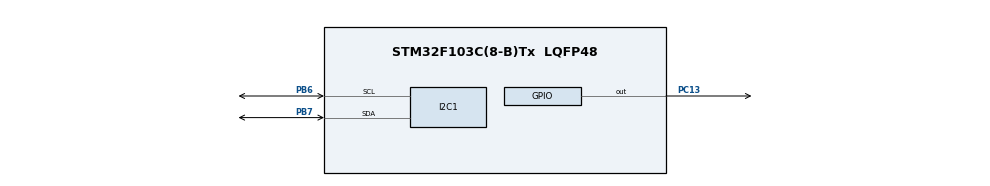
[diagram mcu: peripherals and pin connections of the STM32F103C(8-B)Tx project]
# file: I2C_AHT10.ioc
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I2C1.I2C_Mode=I2C_Fast
Mcu.Family=STM32F1
Mcu.Name=STM32F103C(8-B)Tx
Mcu.Package=LQFP48
NVIC.I2C1_EV_IRQn=true\:0\:0\:false\:false\:true\:true\:true
NVIC.PriorityGroup=NVIC_PRIORITYGROUP_4
NVIC.TIM4_IRQn=true\:0\:0\:false\:false\:true\:true\:true
PA13.Mode=Serial_Wire
PA13.Signal=SYS_JTMS-SWDIO
PA14.Mode=Serial_Wire
PA14.Signal=SYS_JTCK-SWCLK
PB6.Mode=I2C
PB6.Signal=I2C1_SCL
PB7.Mode=I2C
PB7.Signal=I2C1_SDA
PC13-TAMPER-RTC.PinState=GPIO_PIN_SET
PC13-TAMPER-RTC.Signal=GPIO_Output
ProjectManager.HeapSize=0x200
ProjectManager.StackSize=0x400
ProjectManager.TargetToolchain=MDK-ARM V5.27
RCC.APB1Freq_Value=8000000
RCC.APB2Freq_Value=8000000
TIM4.Period=1000-1
TIM4.Prescaler=800-1
VP_TIM4_VS_ClockSourceINT.Mode=Internal
board=custom

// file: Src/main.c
/* USER CODE BEGIN Header */
/**
  ******************************************************************************
  * @file           : main.c
  * @brief          : Main program body
  ******************************************************************************
  * @attention
  *
  * <h2><center>&copy; Copyright (c) 2020 STMicroelectronics.
  * All rights reserved.</center></h2>
  *
  * This software component is licensed by ST under BSD 3-Clause license,
  * the "License"; You may not use this file except in compliance with the
  * License. You may obtain a copy of the License at:
  *                        opensource.org/licenses/BSD-3-Clause
  *
  ******************************************************************************
  */
/* USER CODE END Header */

#include "main.h"

I2C_HandleTypeDef hi2c1;

TIM_HandleTypeDef htim4;

/* USER CODE BEGIN PV */

/* Variables for AHT10 */
uint8_t AHT10_RX_Data[6];
uint32_t AHT10_ADC_Raw;
float AHT10_Temperature;
float AHT10_Humidity;
uint8_t AHT10_TmpHum_Cmd[3] = {0xAC, 0x33, 0x00};

#define AHT10_ADRESS (0x38 << 1) // 0b1110000; Adress[7-bit]Wite/Read[1-bit]

/* Additional vars */
uint8_t T_100ms = 255;
uint8_t AHT10_Switcher = 255;

/* USER CODE END PV */

void SystemClock_Config(void);
static void MX_GPIO_Init(void);
static void MX_I2C1_Init(void);
static void MX_TIM4_Init(void);

/* USER CODE BEGIN 0 */

void HAL_TIM_PeriodElapsedCallback(TIM_HandleTypeDef *htim)
{
 if(htim->Instance == TIM4)
 {
	/* Set every 100ms */
	T_100ms = 255;
 }
}

/* USER CODE END 0 */

int main(void)
{

  /* MCU Configuration--------------------------------------------------------*/

  /* Reset of all peripherals, Initializes the Flash interface and the Systick. */
  HAL_Init();

  /* Configure the system clock */
  SystemClock_Config();

  /* Initialize all configured peripherals */
  MX_GPIO_Init();
  MX_I2C1_Init();
  MX_TIM4_Init();
  /* USER CODE BEGIN 2 */

	/* TIM4 Int. every 100ms */
	HAL_TIM_Base_Start_IT(&htim4);

  /* USER CODE END 2 */

  /* Infinite loop */
  /* USER CODE BEGIN WHILE */
  while (1)
  {

if(T_100ms)
	{
		if(AHT10_Switcher)
			{
				HAL_I2C_Master_Transmit_IT(&hi2c1, AHT10_ADRESS, (uint8_t*)AHT10_TmpHum_Cmd, 3); /* Send command (trigger measuremetns) + parameters */
			}
		else
			{
				HAL_I2C_Master_Receive_IT(&hi2c1, AHT10_ADRESS, (uint8_t*)AHT10_RX_Data, 6); /* Receive data: STATUS[1]:HIMIDITY[2.5]:TEMPERATURE[2.5] */
			}

		if(~AHT10_RX_Data[0] & 0x80)
		{
			/* Convert to Temperature in °C */
			AHT10_ADC_Raw = (((uint32_t)AHT10_RX_Data[3] & 15) << 16) | ((uint32_t)AHT10_RX_Data[4] << 8) | AHT10_RX_Data[5];
			AHT10_Temperature = (float)(AHT10_ADC_Raw * 200.00 / 1048576.00) - 50.00;

//			/* Convert to Relative Humidity in % */
//			AHT10_ADC_Raw = ((uint32_t)AHT10_RX_Data[1] << 12) | ((uint32_t)AHT10_RX_Data[2] << 4) | (AHT10_RX_Data[3] >> 4);
//			AHT10_Humidity = (float)(AHT10_ADC_Raw*100.00/1048576.00);
		}

		AHT10_Switcher = ~AHT10_Switcher; /* Invert */
		GPIOC->ODR ^= GPIO_ODR_ODR13; /* Green LED */
		T_100ms = 0; /* Nulify */
	}

    /* USER CODE END WHILE */

  }
}

void SystemClock_Config(void)
{
  RCC_OscInitTypeDef RCC_OscInitStruct = {0};
  RCC_ClkInitTypeDef RCC_ClkInitStruct = {0};

  /** Initializes the CPU, AHB and APB busses clocks
  */
  RCC_OscInitStruct.OscillatorType = RCC_OSCILLATORTYPE_HSI;
  RCC_OscInitStruct.HSIState = RCC_HSI_ON;
  RCC_OscInitStruct.HSICalibrationValue = RCC_HSICALIBRATION_DEFAULT;
  RCC_OscInitStruct.PLL.PLLState = RCC_PLL_NONE;
  if (HAL_RCC_OscConfig(&RCC_OscInitStruct) != HAL_OK)
  {
    Error_Handler();
  }
  /** Initializes the CPU, AHB and APB busses clocks
  */
  RCC_ClkInitStruct.ClockType = RCC_CLOCKTYPE_HCLK|RCC_CLOCKTYPE_SYSCLK
                              |RCC_CLOCKTYPE_PCLK1|RCC_CLOCKTYPE_PCLK2;
  RCC_ClkInitStruct.SYSCLKSource = RCC_SYSCLKSOURCE_HSI;
  RCC_ClkInitStruct.AHBCLKDivider = RCC_SYSCLK_DIV1;
  RCC_ClkInitStruct.APB1CLKDivider = RCC_HCLK_DIV1;
  RCC_ClkInitStruct.APB2CLKDivider = RCC_HCLK_DIV1;

  if (HAL_RCC_ClockConfig(&RCC_ClkInitStruct, FLASH_LATENCY_0) != HAL_OK)
  {
    Error_Handler();
  }
}

static void MX_I2C1_Init(void)
{

  hi2c1.Instance = I2C1;
  hi2c1.Init.ClockSpeed = 400000;
  hi2c1.Init.DutyCycle = I2C_DUTYCYCLE_2;
  hi2c1.Init.OwnAddress1 = 0;
  hi2c1.Init.AddressingMode = I2C_ADDRESSINGMODE_7BIT;
  hi2c1.Init.DualAddressMode = I2C_DUALADDRESS_DISABLE;
  hi2c1.Init.OwnAddress2 = 0;
  hi2c1.Init.GeneralCallMode = I2C_GENERALCALL_DISABLE;
  hi2c1.Init.NoStretchMode = I2C_NOSTRETCH_DISABLE;
  if (HAL_I2C_Init(&hi2c1) != HAL_OK)
  {
    Error_Handler();
  }

}

static void MX_TIM4_Init(void)
{

  TIM_ClockConfigTypeDef sClockSourceConfig = {0};
  TIM_MasterConfigTypeDef sMasterConfig = {0};

  htim4.Instance = TIM4;
  htim4.Init.Prescaler = 800-1;
  htim4.Init.CounterMode = TIM_COUNTERMODE_UP;
  htim4.Init.Period = 1000-1;
  htim4.Init.ClockDivision = TIM_CLOCKDIVISION_DIV1;
  htim4.Init.AutoReloadPreload = TIM_AUTORELOAD_PRELOAD_DISABLE;
  if (HAL_TIM_Base_Init(&htim4) != HAL_OK)
  {
    Error_Handler();
  }
  sClockSourceConfig.ClockSource = TIM_CLOCKSOURCE_INTERNAL;
  if (HAL_TIM_ConfigClockSource(&htim4, &sClockSourceConfig) != HAL_OK)
  {
    Error_Handler();
  }
  sMasterConfig.MasterOutputTrigger = TIM_TRGO_RESET;
  sMasterConfig.MasterSlaveMode = TIM_MASTERSLAVEMODE_DISABLE;
  if (HAL_TIMEx_MasterConfigSynchronization(&htim4, &sMasterConfig) != HAL_OK)
  {
    Error_Handler();
  }

}

static void MX_GPIO_Init(void)
{
  GPIO_InitTypeDef GPIO_InitStruct = {0};

  /* GPIO Ports Clock Enable */
  __HAL_RCC_GPIOC_CLK_ENABLE();
  __HAL_RCC_GPIOA_CLK_ENABLE();
  __HAL_RCC_GPIOB_CLK_ENABLE();

  /*Configure GPIO pin Output Level */
  HAL_GPIO_WritePin(GPIOC, GPIO_PIN_13, GPIO_PIN_SET);

  /*Configure GPIO pin : PC13 */
  GPIO_InitStruct.Pin = GPIO_PIN_13;
  GPIO_InitStruct.Mode = GPIO_MODE_OUTPUT_PP;
  GPIO_InitStruct.Pull = GPIO_NOPULL;
  GPIO_InitStruct.Speed = GPIO_SPEED_FREQ_LOW;
  HAL_GPIO_Init(GPIOC, &GPIO_InitStruct);

}

void Error_Handler(void)
{
}

/************************ (C) COPYRIGHT STMicroelectronics *****END OF FILE****/
